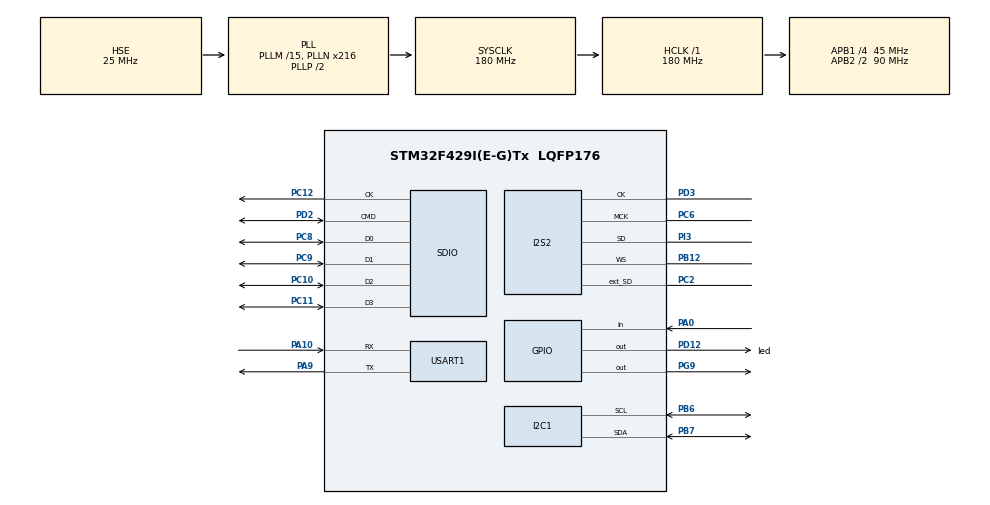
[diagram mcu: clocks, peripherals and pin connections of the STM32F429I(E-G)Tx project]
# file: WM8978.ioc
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Dma.I2S2_EXT_RX.0.Direction=DMA_PERIPH_TO_MEMORY
Dma.I2S2_EXT_RX.0.FIFOMode=DMA_FIFOMODE_DISABLE
Dma.I2S2_EXT_RX.0.Instance=DMA1_Stream3
Dma.I2S2_EXT_RX.0.MemDataAlignment=DMA_MDATAALIGN_HALFWORD
Dma.I2S2_EXT_RX.0.MemInc=DMA_MINC_ENABLE
Dma.I2S2_EXT_RX.0.Mode=DMA_CIRCULAR
Dma.I2S2_EXT_RX.0.PeriphDataAlignment=DMA_PDATAALIGN_HALFWORD
Dma.I2S2_EXT_RX.0.PeriphInc=DMA_PINC_DISABLE
Dma.I2S2_EXT_RX.0.Priority=DMA_PRIORITY_LOW
Dma.Request0=I2S2_EXT_RX
Dma.Request1=SPI2_TX
Dma.Request2=SDIO_RX
Dma.Request3=SDIO_TX
Dma.SDIO_RX.2.Direction=DMA_PERIPH_TO_MEMORY
Dma.SDIO_RX.2.FIFOMode=DMA_FIFOMODE_ENABLE
Dma.SDIO_RX.2.FIFOThreshold=DMA_FIFO_THRESHOLD_FULL
Dma.SDIO_RX.2.Instance=DMA2_Stream3
Dma.SDIO_RX.2.MemBurst=DMA_MBURST_INC4
Dma.SDIO_RX.2.MemDataAlignment=DMA_MDATAALIGN_WORD
Dma.SDIO_RX.2.MemInc=DMA_MINC_ENABLE
Dma.SDIO_RX.2.Mode=DMA_PFCTRL
Dma.SDIO_RX.2.PeriphBurst=DMA_PBURST_INC4
Dma.SDIO_RX.2.PeriphDataAlignment=DMA_PDATAALIGN_WORD
Dma.SDIO_RX.2.PeriphInc=DMA_PINC_DISABLE
Dma.SDIO_RX.2.Priority=DMA_PRIORITY_LOW
Dma.SDIO_TX.3.Direction=DMA_MEMORY_TO_PERIPH
Dma.SDIO_TX.3.FIFOMode=DMA_FIFOMODE_ENABLE
Dma.SDIO_TX.3.FIFOThreshold=DMA_FIFO_THRESHOLD_FULL
Dma.SDIO_TX.3.Instance=DMA2_Stream6
Dma.SDIO_TX.3.MemBurst=DMA_MBURST_INC4
Dma.SDIO_TX.3.MemDataAlignment=DMA_MDATAALIGN_WORD
Dma.SDIO_TX.3.MemInc=DMA_MINC_ENABLE
Dma.SDIO_TX.3.Mode=DMA_PFCTRL
Dma.SDIO_TX.3.PeriphBurst=DMA_PBURST_INC4
Dma.SDIO_TX.3.PeriphDataAlignment=DMA_PDATAALIGN_WORD
Dma.SDIO_TX.3.PeriphInc=DMA_PINC_DISABLE
Dma.SDIO_TX.3.Priority=DMA_PRIORITY_LOW
Dma.SPI2_TX.1.Direction=DMA_MEMORY_TO_PERIPH
Dma.SPI2_TX.1.FIFOMode=DMA_FIFOMODE_DISABLE
Dma.SPI2_TX.1.Instance=DMA1_Stream4
Dma.SPI2_TX.1.MemDataAlignment=DMA_MDATAALIGN_HALFWORD
Dma.SPI2_TX.1.MemInc=DMA_MINC_ENABLE
Dma.SPI2_TX.1.Mode=DMA_CIRCULAR
Dma.SPI2_TX.1.PeriphDataAlignment=DMA_PDATAALIGN_HALFWORD
Dma.SPI2_TX.1.PeriphInc=DMA_PINC_DISABLE
Dma.SPI2_TX.1.Priority=DMA_PRIORITY_LOW
I2S2.ErrorAudioFreq=1.72 %
I2S2.FullDuplexMode=I2S_FULLDUPLEXMODE_ENABLE
I2S2.Instance=SPI$Index
I2S2.RealAudioFreq=8.138 KHz
I2S2.VirtualMode=I2S_MODE_MASTER
Mcu.Family=STM32F4
Mcu.Name=STM32F429I(E-G)Tx
Mcu.Package=LQFP176
NVIC.DMA1_Stream3_IRQn=true\:0\:0\:false\:false\:true\:false
NVIC.DMA1_Stream4_IRQn=true\:0\:0\:false\:false\:true\:false
NVIC.DMA2_Stream3_IRQn=true\:0\:0\:false\:false\:true\:false
NVIC.DMA2_Stream6_IRQn=true\:0\:0\:false\:false\:true\:false
NVIC.PriorityGroup=NVIC_PRIORITYGROUP_4
NVIC.SDIO_IRQn=true\:0\:0\:false\:false\:true\:true
NVIC.SPI2_IRQn=true\:0\:0\:false\:false\:true\:true
NVIC.USART1_IRQn=true\:0\:0\:false\:false\:true\:true
PA0/WKUP.Signal=GPIO_Input
PA10.Mode=Asynchronous
PA10.Signal=USART1_RX
PA9.Mode=Asynchronous
PA9.Signal=USART1_TX
PB12.Mode=Full_Duplex_Master
PB12.Signal=I2S2_WS
PB6.Mode=I2C
PB6.Signal=I2C1_SCL
PB7.Mode=I2C
PB7.Signal=I2C1_SDA
PC10.Mode=SD_4_bits_Wide_bus
PC10.Signal=SDIO_D2
PC11.Mode=SD_4_bits_Wide_bus
PC11.Signal=SDIO_D3
PC12.Mode=SD_4_bits_Wide_bus
PC12.Signal=SDIO_CK
PC2.Mode=Full_Duplex_Master
PC2.Signal=I2S2_ext_SD
PC6.Mode=Master_Clock_Activated
PC6.Signal=I2S2_MCK
PC8.Mode=SD_4_bits_Wide_bus
PC8.Signal=SDIO_D0
PC9.Mode=SD_4_bits_Wide_bus
PC9.Signal=SDIO_D1
PD12.GPIO_Label=led
PD12.Signal=GPIO_Output
PD2.Mode=SD_4_bits_Wide_bus
PD2.Signal=SDIO_CMD
PD3.Mode=Full_Duplex_Master
PD3.Signal=I2S2_CK
PG9.Signal=GPIO_Output
PH0/OSC_IN.Mode=HSE-External-Oscillator
PH0/OSC_IN.Signal=RCC_OSC_IN
PH1/OSC_OUT.Mode=HSE-External-Oscillator
PH1/OSC_OUT.Signal=RCC_OSC_OUT
PI3.Mode=Full_Duplex_Master
PI3.Signal=I2S2_SD
ProjectManager.HeapSize=0x400
ProjectManager.StackSize=0x800
ProjectManager.TargetToolchain=Other Toolchains (GPDSC)
RCC.48MHZClocksFreq_Value=45000000
RCC.AHBFreq_Value=180000000
RCC.APB1CLKDivider=RCC_HCLK_DIV4
RCC.APB1Freq_Value=45000000
RCC.APB1TimFreq_Value=90000000
RCC.APB2CLKDivider=RCC_HCLK_DIV2
RCC.APB2Freq_Value=90000000
RCC.APB2TimFreq_Value=180000000
RCC.CortexFreq_Value=180000000
RCC.HCLKFreq_Value=180000000
RCC.HSE_VALUE=25000000
RCC.HSI_VALUE=16000000
RCC.LSE_VALUE=32768
RCC.PLLI2SN=60
RCC.PLLM=15
RCC.PLLN=216
RCC.PLLQ=8
RCC.PLLSourceVirtual=RCC_PLLSOURCE_HSE
RCC.SYSCLKFreq_VALUE=180000000
RCC.SYSCLKSource=RCC_SYSCLKSOURCE_PLLCLK
RCC.VCOOutputFreq_Value=360000000
SDIO.ClockDiv=7
USART1.VirtualMode=VM_ASYNC
board=WM8978

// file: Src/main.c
/**
  ******************************************************************************
  * @file           : main.c
  * @brief          : Main program body
  ******************************************************************************
  ** This notice applies to any and all portions of this file
  * that are not between comment pairs USER CODE BEGIN and
  * USER CODE END. Other portions of this file, whether
  * inserted by the user or by software development tools
  * are owned by their respective copyright owners.
  *
  * COPYRIGHT(c) 2018 STMicroelectronics
  *
  * Redistribution and use in source and binary forms, with or without modification,
  * are permitted provided that the following conditions are met:
  *   1. Redistributions of source code must retain the above copyright notice,
  *      this list of conditions and the following disclaimer.
  *   2. Redistributions in binary form must reproduce the above copyright notice,
  *      this list of conditions and the following disclaimer in the documentation
  *      and/or other materials provided with the distribution.
  *   3. Neither the name of STMicroelectronics nor the names of its contributors
  *      may be used to endorse or promote products derived from this software
  *      without specific prior written permission.
  *
  * THIS SOFTWARE IS PROVIDED BY THE COPYRIGHT HOLDERS AND CONTRIBUTORS "AS IS"
  * AND ANY EXPRESS OR IMPLIED WARRANTIES, INCLUDING, BUT NOT LIMITED TO, THE
  * IMPLIED WARRANTIES OF MERCHANTABILITY AND FITNESS FOR A PARTICULAR PURPOSE ARE
  * DISCLAIMED. IN NO EVENT SHALL THE COPYRIGHT HOLDER OR CONTRIBUTORS BE LIABLE
  * FOR ANY DIRECT, INDIRECT, INCIDENTAL, SPECIAL, EXEMPLARY, OR CONSEQUENTIAL
  * DAMAGES (INCLUDING, BUT NOT LIMITED TO, PROCUREMENT OF SUBSTITUTE GOODS OR
  * SERVICES; LOSS OF USE, DATA, OR PROFITS; OR BUSINESS INTERRUPTION) HOWEVER
  * CAUSED AND ON ANY THEORY OF LIABILITY, WHETHER IN CONTRACT, STRICT LIABILITY,
  * OR TORT (INCLUDING NEGLIGENCE OR OTHERWISE) ARISING IN ANY WAY OUT OF THE USE
  * OF THIS SOFTWARE, EVEN IF ADVISED OF THE POSSIBILITY OF SUCH DAMAGE.
  *
  ******************************************************************************
  */
#include "main.h"
#include "stm32f4xx_hal.h"
#include "dma.h"
#include "i2c.h"
#include "i2s.h"
#include "sdio.h"
#include "usart.h"
#include "gpio.h"

/* USER CODE BEGIN PV */
/* Private variables ---------------------------------------------------------*/

/* USER CODE END PV */

void SystemClock_Config(void);

/* USER CODE BEGIN PFP */
/* Private function prototypes -----------------------------------------------*/

/* USER CODE END PFP */

int main(void)
{

  /* MCU Configuration----------------------------------------------------------*/

  /* Reset of all peripherals, Initializes the Flash interface and the Systick. */
  HAL_Init();

  /* Configure the system clock */
  SystemClock_Config();

  /* Initialize all configured peripherals */
  MX_GPIO_Init();
  MX_DMA_Init();
  MX_USART1_UART_Init();
  MX_SDIO_SD_Init();
  MX_I2C1_Init();
  MX_I2S2_Init();

  /* Infinite loop */
  while (1)
  {

  /* USER CODE BEGIN 3 */

	  HAL_GPIO_TogglePin(led_GPIO_Port, led_Pin);
	  HAL_Delay(500);

  }
  /* USER CODE END 3 */

}

void SystemClock_Config(void)
{

  RCC_OscInitTypeDef RCC_OscInitStruct;
  RCC_ClkInitTypeDef RCC_ClkInitStruct;
  RCC_PeriphCLKInitTypeDef PeriphClkInitStruct;

    /**Configure the main internal regulator output voltage
    */
  __HAL_RCC_PWR_CLK_ENABLE();

  __HAL_PWR_VOLTAGESCALING_CONFIG(PWR_REGULATOR_VOLTAGE_SCALE1);

    /**Initializes the CPU, AHB and APB busses clocks
    */
  RCC_OscInitStruct.OscillatorType = RCC_OSCILLATORTYPE_HSE;
  RCC_OscInitStruct.HSEState = RCC_HSE_ON;
  RCC_OscInitStruct.PLL.PLLState = RCC_PLL_ON;
  RCC_OscInitStruct.PLL.PLLSource = RCC_PLLSOURCE_HSE;
  RCC_OscInitStruct.PLL.PLLM = 15;
  RCC_OscInitStruct.PLL.PLLN = 216;
  RCC_OscInitStruct.PLL.PLLP = RCC_PLLP_DIV2;
  RCC_OscInitStruct.PLL.PLLQ = 8;
  if (HAL_RCC_OscConfig(&RCC_OscInitStruct) != HAL_OK)
  {
    _Error_Handler(__FILE__, __LINE__);
  }

    /**Activate the Over-Drive mode
    */
  if (HAL_PWREx_EnableOverDrive() != HAL_OK)
  {
    _Error_Handler(__FILE__, __LINE__);
  }

    /**Initializes the CPU, AHB and APB busses clocks
    */
  RCC_ClkInitStruct.ClockType = RCC_CLOCKTYPE_HCLK|RCC_CLOCKTYPE_SYSCLK
                              |RCC_CLOCKTYPE_PCLK1|RCC_CLOCKTYPE_PCLK2;
  RCC_ClkInitStruct.SYSCLKSource = RCC_SYSCLKSOURCE_PLLCLK;
  RCC_ClkInitStruct.AHBCLKDivider = RCC_SYSCLK_DIV1;
  RCC_ClkInitStruct.APB1CLKDivider = RCC_HCLK_DIV4;
  RCC_ClkInitStruct.APB2CLKDivider = RCC_HCLK_DIV2;

  if (HAL_RCC_ClockConfig(&RCC_ClkInitStruct, FLASH_LATENCY_5) != HAL_OK)
  {
    _Error_Handler(__FILE__, __LINE__);
  }

  PeriphClkInitStruct.PeriphClockSelection = RCC_PERIPHCLK_I2S;
  PeriphClkInitStruct.PLLI2S.PLLI2SN = 60;
  PeriphClkInitStruct.PLLI2S.PLLI2SR = 2;
  if (HAL_RCCEx_PeriphCLKConfig(&PeriphClkInitStruct) != HAL_OK)
  {
    _Error_Handler(__FILE__, __LINE__);
  }

    /**Configure the Systick interrupt time
    */
  HAL_SYSTICK_Config(HAL_RCC_GetHCLKFreq()/1000);

    /**Configure the Systick
    */
  HAL_SYSTICK_CLKSourceConfig(SYSTICK_CLKSOURCE_HCLK);

  /* SysTick_IRQn interrupt configuration */
  HAL_NVIC_SetPriority(SysTick_IRQn, 0, 0);
}

void _Error_Handler(char *file, int line)
{
  while(1)
  {
  }
}

/************************ (C) COPYRIGHT STMicroelectronics *****END OF FILE****/
